# liliumSOC1_sysctrl register map
Vendor: Nordic Semiconductor; Series: liliumSOC1; File version: 1
Registers are 32-bit, read-write, reset 0x0 unless marked. A register's access mark holds for its fields unless they carry their own. Offsets are from the block's base; [hi:lo] are bit positions; lines under a group give offsets from that group; {n}, {i} and the like mark numbered series; 'fields as' and 'values as' point back to an identical list.

## EXMEE_S — EXternal Memory Encryption Engine
Base 0x5F094000
0x00 TASKS_START wo — Start EXMEE operations.
  [0] TASKS_START
    1=Trigger task
0x04 TASKS_STOP wo — Stop EXMEE operations.
  [0] TASKS_STOP
    1=Trigger task
0x08 TASKS_RESET wo — Reset the EXMEE and its registers. Reset the FSM to default values.
  [0] TASKS_RESET
    1=Trigger task
0x0C TASKS_COMMIT wo — Pad data buffer and commit to memory.
  [0] TASKS_COMMIT
    1=Trigger task
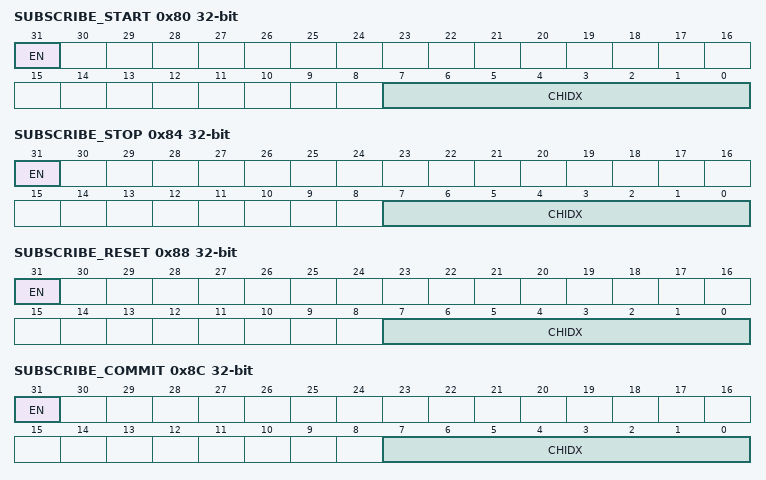
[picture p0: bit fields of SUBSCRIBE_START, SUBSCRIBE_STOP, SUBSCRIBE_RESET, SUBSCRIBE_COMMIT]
0x80 SUBSCRIBE_START — Subscribe configuration for task START
  [31] EN
    0=Disabled (Disable subscription); 1=Enabled (Enable subscription)
  [7:0] CHIDX — DPPI channel that task START will subscribe to
0x84 SUBSCRIBE_STOP — Subscribe configuration for task STOP
  [31] EN
    values as SUBSCRIBE_START.EN
  [7:0] CHIDX — DPPI channel that task STOP will subscribe to
0x88 SUBSCRIBE_RESET — Subscribe configuration for task RESET
  [31] EN
    values as SUBSCRIBE_START.EN
  [7:0] CHIDX — DPPI channel that task RESET will subscribe to
0x8C SUBSCRIBE_COMMIT — Subscribe configuration for task COMMIT
  [31] EN
    values as SUBSCRIBE_START.EN
  [7:0] CHIDX — DPPI channel that task COMMIT will subscribe to
0x100 EVENTS_STOPPED — Unspecified
  [0] EVENTS_STOPPED
    0=NotGenerated (Event not generated); 1=Generated (Event generated)
0x104 EVENTS_READACCESS — The read access event fires when a read access to the decrypted memory window is received
  [0] EVENTS_READACCESS
    values as EVENTS_STOPPED.EVENTS_STOPPED
0x108 EVENTS_WRITEACCESS — The write access event fires when a write access to the decrypted memory window is received
  [0] EVENTS_WRITEACCESS
    values as EVENTS_STOPPED.EVENTS_STOPPED
0x10C EVENTS_INVALIDKEYREGION — The invalid key region event fires if the address of the AXI transaction does not correspond with any of the regions there is keys for in the key register
  [0] EVENTS_INVALIDKEYREGION
    values as EVENTS_STOPPED.EVENTS_STOPPED
0x110 EVENTS_INCREMENTCOUNTER — The increment counter event fires when the counter needs to be incremented. Typically when an encryption operation has completed, before the next encryption operation can start
  [0] EVENTS_INCREMENTCOUNTER
    values as EVENTS_STOPPED.EVENTS_STOPPED
0x114 EVENTS_DATARECEIVED — The data received event fires when an AXI operation happens on the slave port, and the data received is the first data in a new 512b chunk
  [0] EVENTS_DATARECEIVED
    values as EVENTS_STOPPED.EVENTS_STOPPED
0x118 EVENTS_CIPHERTEXTREADY — The ciphertext ready event fires when the data is encrypted and the ciphertext is ready in the CIPHERTEXT register
  [0] EVENTS_CIPHERTEXTREADY
    values as EVENTS_STOPPED.EVENTS_STOPPED
0x11C EVENTS_NONCEREADY — The nonce ready event fires when the nonce is ready in the NONCE register
  [0] EVENTS_NONCEREADY
    values as EVENTS_STOPPED.EVENTS_STOPPED
0x120 EVENTS_WRITECOMPLETE — The write complete event fires when the ciphertext and counter has been written to the external memory
  [0] EVENTS_WRITECOMPLETE
    values as EVENTS_STOPPED.EVENTS_STOPPED
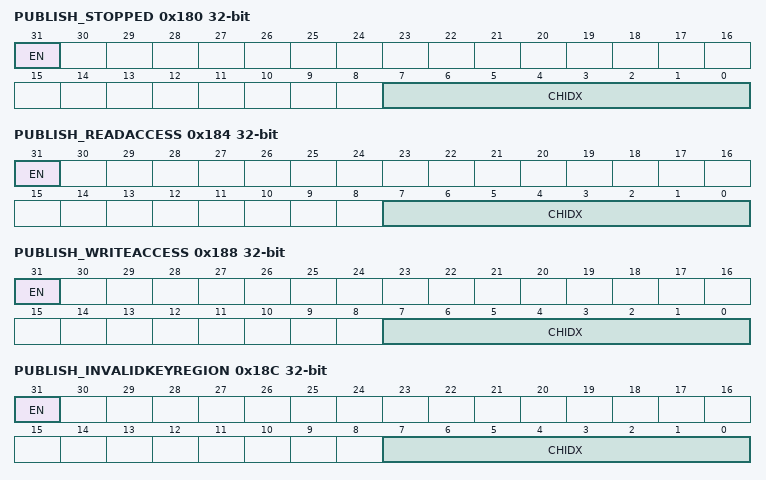
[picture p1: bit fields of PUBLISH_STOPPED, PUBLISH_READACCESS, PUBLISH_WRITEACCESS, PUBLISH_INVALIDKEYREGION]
0x180 PUBLISH_STOPPED — Publish configuration for event STOPPED
  [31] EN
    0=Disabled (Disable publishing); 1=Enabled (Enable publishing)
  [7:0] CHIDX — DPPI channel that event STOPPED will publish to
0x184 PUBLISH_READACCESS — Publish configuration for event READACCESS
  [31] EN
    values as PUBLISH_STOPPED.EN
  [7:0] CHIDX — DPPI channel that event READACCESS will publish to
0x188 PUBLISH_WRITEACCESS — Publish configuration for event WRITEACCESS
  [31] EN
    values as PUBLISH_STOPPED.EN
  [7:0] CHIDX — DPPI channel that event WRITEACCESS will publish to
0x18C PUBLISH_INVALIDKEYREGION — Publish configuration for event INVALIDKEYREGION
  [31] EN
    values as PUBLISH_STOPPED.EN
  [7:0] CHIDX — DPPI channel that event INVALIDKEYREGION will publish to
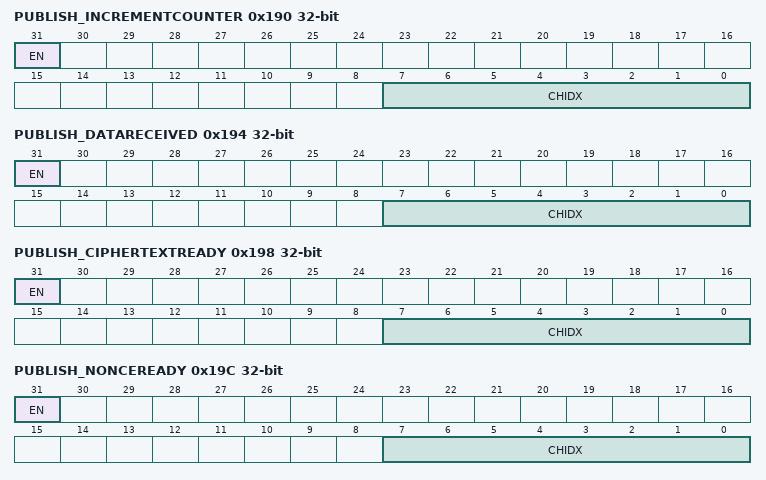
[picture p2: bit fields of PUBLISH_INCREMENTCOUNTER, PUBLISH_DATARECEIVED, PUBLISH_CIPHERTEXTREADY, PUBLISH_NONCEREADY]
0x190 PUBLISH_INCREMENTCOUNTER — Publish configuration for event INCREMENTCOUNTER
  [31] EN
    values as PUBLISH_STOPPED.EN
  [7:0] CHIDX — DPPI channel that event INCREMENTCOUNTER will publish to
0x194 PUBLISH_DATARECEIVED — Publish configuration for event DATARECEIVED
  [31] EN
    values as PUBLISH_STOPPED.EN
  [7:0] CHIDX — DPPI channel that event DATARECEIVED will publish to
0x198 PUBLISH_CIPHERTEXTREADY — Publish configuration for event CIPHERTEXTREADY
  [31] EN
    values as PUBLISH_STOPPED.EN
  [7:0] CHIDX — DPPI channel that event CIPHERTEXTREADY will publish to
0x19C PUBLISH_NONCEREADY — Publish configuration for event NONCEREADY
  [31] EN
    values as PUBLISH_STOPPED.EN
  [7:0] CHIDX — DPPI channel that event NONCEREADY will publish to
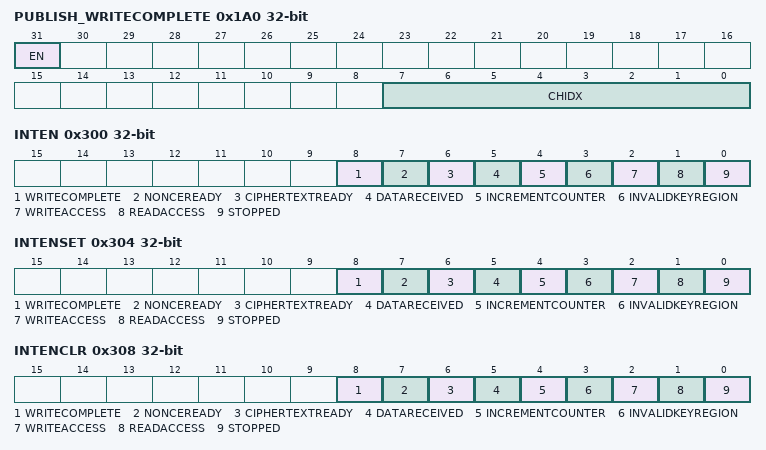
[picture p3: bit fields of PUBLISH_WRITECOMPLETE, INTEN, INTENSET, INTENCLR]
0x1A0 PUBLISH_WRITECOMPLETE — Publish configuration for event WRITECOMPLETE
  [31] EN
    values as PUBLISH_STOPPED.EN
  [7:0] CHIDX — DPPI channel that event WRITECOMPLETE will publish to
0x200 SHORTS — Shortcuts between local events and tasks
  [0] NONCEREADY_START — Shortcut between event NONCEREADY and task START
    0=Disabled (Disable shortcut); 1=Enabled (Enable shortcut)
0x300 INTEN — Enable or disable interrupt
  [all] fields
    0=Disabled; 1=Enabled
  [8] WRITECOMPLETE — Enable or disable interrupt for event WRITECOMPLETE
  [7] NONCEREADY — Enable or disable interrupt for event NONCEREADY
  [6] CIPHERTEXTREADY — Enable or disable interrupt for event CIPHERTEXTREADY
  [5] DATARECEIVED — Enable or disable interrupt for event DATARECEIVED
  [4] INCREMENTCOUNTER — Enable or disable interrupt for event INCREMENTCOUNTER
  [3] INVALIDKEYREGION — Enable or disable interrupt for event INVALIDKEYREGION
  [2] WRITEACCESS — Enable or disable interrupt for event WRITEACCESS
  [1] READACCESS — Enable or disable interrupt for event READACCESS
  [0] STOPPED — Enable or disable interrupt for event STOPPED
0x304 INTENSET — Enable interrupt
  [all] fields
    on read: 0=Disabled (Read: Disabled); 1=Enabled (Read: Enabled) | on write: 1=Set (Enable)
  [8] WRITECOMPLETE — Write '1' to enable interrupt for event WRITECOMPLETE
  [7] NONCEREADY — Write '1' to enable interrupt for event NONCEREADY
  [6] CIPHERTEXTREADY — Write '1' to enable interrupt for event CIPHERTEXTREADY
  [5] DATARECEIVED — Write '1' to enable interrupt for event DATARECEIVED
  [4] INCREMENTCOUNTER — Write '1' to enable interrupt for event INCREMENTCOUNTER
  [3] INVALIDKEYREGION — Write '1' to enable interrupt for event INVALIDKEYREGION
  [2] WRITEACCESS — Write '1' to enable interrupt for event WRITEACCESS
  [1] READACCESS — Write '1' to enable interrupt for event READACCESS
  [0] STOPPED — Write '1' to enable interrupt for event STOPPED
0x308 INTENCLR — Disable interrupt
  [all] fields
    on read: 0=Disabled (Read: Disabled); 1=Enabled (Read: Enabled) | on write: 1=Clear (Disable)
  [8] WRITECOMPLETE — Write '1' to disable interrupt for event WRITECOMPLETE
  [7] NONCEREADY — Write '1' to disable interrupt for event NONCEREADY
  [6] CIPHERTEXTREADY — Write '1' to disable interrupt for event CIPHERTEXTREADY
  [5] DATARECEIVED — Write '1' to disable interrupt for event DATARECEIVED
  [4] INCREMENTCOUNTER — Write '1' to disable interrupt for event INCREMENTCOUNTER
  [3] INVALIDKEYREGION — Write '1' to disable interrupt for event INVALIDKEYREGION
  [2] WRITEACCESS — Write '1' to disable interrupt for event WRITEACCESS
  [1] READACCESS — Write '1' to disable interrupt for event READACCESS
  [0] STOPPED — Write '1' to disable interrupt for event STOPPED
0x500 ENABLE — Enable the EXMEE peripheral.
  [0] ENABLE — Enable or disable EXMEE
    0=Disabled (Disable EXMEE); 1=Enabled (Enable EXMEE)
0x510 PAGE group — Memory pages the EXMEE works on
  0x00 UNENCRYPTED group — Unencrypted memory access page. This area of memory provides an unencrypted page into the secure memory region.
    0x00 START — Start address for input memory page
      [31:0] ADDRESS — Start address of page
    0x04 END — End address for input memory page
      [31:0] ADDRESS — End address of page
  0x08 ENCRYPTED group — Secure memory access page. This area of memory stores the encrypted data.
    0x00 START — Start address for output memory page
      [31:0] ADDRESS — Start address of page
    0x04 END — End address for output memory page
      [31:0] ADDRESS — End address of page
0x530 TRANSACTION group — Information about the currently processed transaction
  0x00 ADDRESS ro — Target address in external memory of the currently processed AXI transaction
    [0] ADDRESS — Address in EXMIF
  {0x8+4j} COUNTER[{j}] (j=0..1) — Description collection: 64 bit write counter
    [31:0] COUNTER — The n-th word of the 64 bit counter value
  {0x10+4j} PLAINTEXT[{j}] (j=0..3) ro — Description collection: 128 bit plaintext register.
    [31:0] WORD — The n-th word of the 128 bit plaintext input
  {0x20+4j} CIPHERTEXT[{j}] (j=0..3) ro — Description collection: 128 bit ciphertext register.
    [31:0] WORD — The n-th word of the 128 bit ciphertext input
  {0x30+4j} NONCE[{j}] (j=0..3) — Description collection: 128 bit nonce register.
    [31:0] WORD — The n-th word of the 128 bit nonce input
{0x600+0x20*i} REGION[{i}] (i=0..15) group — Encryption region n
  0x00 START — Description cluster: Start offset relative to memory window for encryption region n
    [31:0] OFFSET — Start offset of encryption region
  0x04 END — Description cluster: End offset relative to memory window for encryption region n
    [31:0] OFFSET — End offset of encryption region
  0x08 COUNTER — Description cluster: Address offset where the write counters for encryption region n should be stored
    [31:0] OFFSET — Counter offset of encryption region
  0x0C NONCEMODE — Description cluster: Nonce mode for encryption region n
    [0] MODE — Nonce mode for encryption region. This register enables the EVENTS_NONCEREADY to TASKS_START shortcut
      0=AUTO (EXMEE does not wait before reading NONCE register); 1=WAIT (EXMEE waits for TASKS_START before reading NONCE register)
  {0x10+4j} KEY[{j}] (j=0..3) wo — Description collection: 128b key for encryption region n
    [31:0] WORD — The o-th word of the 128b key
